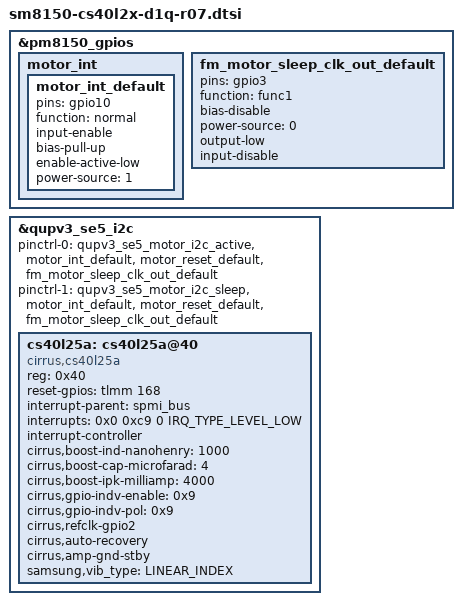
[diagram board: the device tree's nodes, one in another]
/* Copyright (c) 2016, The Linux Foundation. All rights reserved.
 *
 * This program is free software; you can redistribute it and/or modify
 * it under the terms of the GNU General Public License version 2 and
 * only version 2 as published by the Free Software Foundation.
 *
 * This program is distributed in the hope that it will be useful,
 * but WITHOUT ANY WARRANTY; without even the implied warranty of
 * MERCHANTABILITY or FITNESS FOR A PARTICULAR PURPOSE.  See the
 * GNU General Public License for more details.
 * 
 * 
 */

&pm8150_gpios {
	motor_int {
		motor_int_default: motor_int_default {
			pins = "gpio10";
			function = "normal";
			input-enable;
			bias-pull-up;
			enable-active-low;
			power-source = <1>;
		};
	};

	fm_motor_sleep_clk_out_default: fm_motor_sleep_clk_out_default {
		pins = "gpio3";
		function = "func1";
		bias-disable;
		power-source = <0>;
		output-low;
		input-disable;
	};
};

&qupv3_se5_i2c {
	status = "okay";
	pinctrl-names = "default", "sleep";
	pinctrl-0 = <&qupv3_se5_motor_i2c_active &motor_int_default &motor_reset_default &fm_motor_sleep_clk_out_default>;
	pinctrl-1 = <&qupv3_se5_motor_i2c_sleep &motor_int_default &motor_reset_default &fm_motor_sleep_clk_out_default>;

	cs40l25a: cs40l25a@40 {
		status = "okay";
		compatible = "cirrus,cs40l25a";
		reg = <0x40>;
		reset-gpios = <&tlmm 168 0>; // MOTOR_RST
		interrupt-parent = <&spmi_bus>;
		interrupts = <0x0 0xc9 0 IRQ_TYPE_LEVEL_LOW>; // MOTOR_INT
		interrupt-names = "default";
		interrupt-controller;
		cirrus,boost-ind-nanohenry = <1000>;
		cirrus,boost-cap-microfarad = <4>;
		cirrus,boost-ipk-milliamp = <4000>;
		cirrus,gpio-indv-enable = <0x9>;
		cirrus,gpio-indv-pol = <0x9>;
		cirrus,refclk-gpio2;
		cirrus,auto-recovery;
		cirrus,amp-gnd-stby;
		samsung,vib_type = "LINEAR_INDEX";	// using cirrus motor IC and 1040 motor
	};
};
